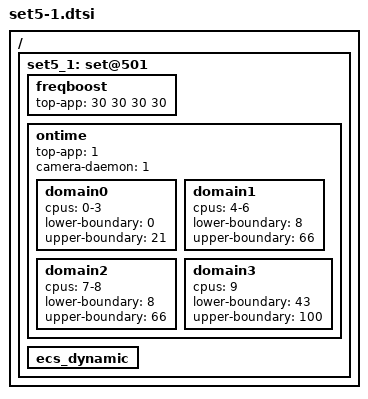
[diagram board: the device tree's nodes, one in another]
/ {
	/* camera mode - touch boost */
	set5_1: set@501 {
		/* Boosting margin applied to frequency selection */
		freqboost {	   		/* LIT MED-L MED-H BIG */
			top-app         	= < 30 30 30 30>;
		};

		/* Ontime Migration */
		ontime {
			top-app			= <1>;
			camera-daemon	= <1>;

			domain0 {
				cpus = "0-3";
				lower-boundary = <0>;
				upper-boundary = <21>;
			};
			domain1 {
				cpus = "4-6";
				lower-boundary = <8>;
				upper-boundary = <66>;
			};
			domain2 {
				cpus = "7-8";
				lower-boundary = <8>;
				upper-boundary = <66>;
			};
			domain3 {
				cpus = "9";
				lower-boundary = <43>;
				upper-boundary = <100>;
			};
		};

		ecs_dynamic { };
	};
};
